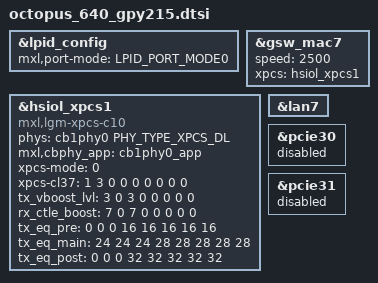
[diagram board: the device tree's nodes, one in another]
// SPDX-License-Identifier: GPL-2.0
/*
 * This file created for LGMC bring up only.
 * It will be removed after bring up.
 *
 * Copyright (C) 2024 MaxLinear, Inc.
 */

&lpid_config {
	mxl,port-mode = <LPID_PORT_MODE0>;
};

&gsw_mac7 {
	speed = <2500>;
	xpcs = <&hsiol_xpcs1>;
};

&hsiol_xpcs1 {
	status = "okay";

	compatible = "mxl,lgm-xpcs-c10";
	phys = <&cb1phy0 PHY_TYPE_XPCS_DL>;
	mxl,cbphy_app = <&cb1phy0_app>;
	/delete-property/ slave;

	xpcs-mode = <0>;
	xpcs-cl37 = <1 3 0 0 0 0 0 0 0>; /* <0> - disable, <1> - SGMII MAC side, <2> - SGMII PHY side, <3> - BaseX */
	tx_vboost_lvl = <3 0 3 0 0 0 0 0>;
	rx_ctle_boost = <7 0 7 0 0 0 0 0>;
	tx_eq_pre = <0 0 0 16 16 16 16 16>;
	tx_eq_main = <24 24 24 28 28 28 28 28>;
	tx_eq_post = <0 0 0 32 32 32 32 32>;
};

&lan7 {
	status = "okay";
};

&pcie30 {
	status = "disabled";
};

&pcie31 {
	status = "disabled";
};
